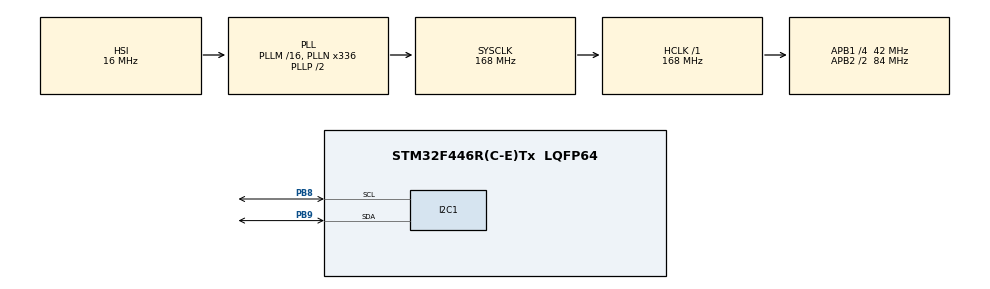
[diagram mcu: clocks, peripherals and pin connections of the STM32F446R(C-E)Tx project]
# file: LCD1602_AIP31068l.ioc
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I2C1.I2C_Mode=I2C_Fast
Mcu.Family=STM32F4
Mcu.Name=STM32F446R(C-E)Tx
Mcu.Package=LQFP64
NVIC.PriorityGroup=NVIC_PRIORITYGROUP_4
PA13.Mode=Serial_Wire
PA13.Signal=SYS_JTMS-SWDIO
PA14.Mode=Serial_Wire
PA14.Signal=SYS_JTCK-SWCLK
PB8.Mode=I2C
PB8.Signal=I2C1_SCL
PB9.Mode=I2C
PB9.Signal=I2C1_SDA
ProjectManager.HeapSize=0x200
ProjectManager.StackSize=0x400
ProjectManager.TargetToolchain=MDK-ARM V5.32
RCC.AHBFreq_Value=168000000
RCC.APB1CLKDivider=RCC_HCLK_DIV4
RCC.APB1Freq_Value=42000000
RCC.APB1TimFreq_Value=84000000
RCC.APB2CLKDivider=RCC_HCLK_DIV2
RCC.APB2Freq_Value=84000000
RCC.APB2TimFreq_Value=168000000
RCC.CortexFreq_Value=168000000
RCC.HCLKFreq_Value=168000000
RCC.PLLN=336
RCC.SYSCLKFreq_VALUE=168000000
RCC.SYSCLKSource=RCC_SYSCLKSOURCE_PLLCLK
RCC.USBFreq_Value=168000000
RCC.VCOOutputFreq_Value=336000000
board=custom

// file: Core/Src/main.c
/* USER CODE BEGIN Header */
/**
  ******************************************************************************
  * @file           : main.c
  * @brief          : Main program body
  ******************************************************************************
  * @attention
  *
  * Copyright (c) 2026 STMicroelectronics.
  * All rights reserved.
  *
  * This software is licensed under terms that can be found in the LICENSE file
  * in the root directory of this software component.
  * If no LICENSE file comes with this software, it is provided AS-IS.
  *
  ******************************************************************************
  */
/* USER CODE END Header */
#include "main.h"
#include "i2c.h"
#include "gpio.h"

/* USER CODE BEGIN Includes */
#include "dwt_delay.h"
#include "lcd1602_i2c_aip31068l.h"
/* USER CODE END Includes */

void SystemClock_Config(void);

int main(void)
{

  /* MCU Configuration--------------------------------------------------------*/

  /* Reset of all peripherals, Initializes the Flash interface and the Systick. */
  HAL_Init();

  /* Configure the system clock */
  SystemClock_Config();

  /* Initialize all configured peripherals */
  MX_GPIO_Init();
  MX_I2C1_Init();
  /* USER CODE BEGIN 2 */

	/**
   * IMPORTANT:
   * Initialize DWT after clocks so SystemCoreClock is correct.
   * DWT requires TRCENA to access counters. [2](http://www.dinceraydin.com/lcd/commands.htm)
   */
  (void)DWT_Delay_Init();

/* Initialize LCD (includes ~60ms power-on wait and basic init commands) */
  lcd_init();
  lcd_backlight_init();              // initialize PCA9633 backlight driver (PCA9633 must be mounted on the module)
  lcd_backlight_set_brightness(255); // 0..255 (try 255 for max)

  lcd_clear();
  lcd_set_cursor(0, 0);
	lcd_puts("STM32F446RE");
  lcd_set_cursor(0, 1);
  lcd_puts("DFR0555 + DWT");

 /* Small demo: shift display right then left */
  DWT_DelayUs(1000000);   /* 1000 ms */
  lcd_scroll(true, 3);
  DWT_DelayUs(1000000);
  lcd_scroll(false, 3);

  /* Custom character demo */
  const uint8_t smile[8] = {
      0b00000,
      0b01010,
      0b01010,
      0b00000,
      0b10001,
      0b01110,
      0b00000,
      0b00000
  };
  lcd_create_char(0, smile);
  lcd_set_cursor(15, 1);
  lcd_put_custom(0);

  /* USER CODE END 2 */

  /* Infinite loop */
  while (1)
  {

  }
}

void SystemClock_Config(void)
{
  RCC_OscInitTypeDef RCC_OscInitStruct = {0};
  RCC_ClkInitTypeDef RCC_ClkInitStruct = {0};

  /** Configure the main internal regulator output voltage
  */
  __HAL_RCC_PWR_CLK_ENABLE();
  __HAL_PWR_VOLTAGESCALING_CONFIG(PWR_REGULATOR_VOLTAGE_SCALE1);

  /** Initializes the RCC Oscillators according to the specified parameters
  * in the RCC_OscInitTypeDef structure.
  */
  RCC_OscInitStruct.OscillatorType = RCC_OSCILLATORTYPE_HSI;
  RCC_OscInitStruct.HSIState = RCC_HSI_ON;
  RCC_OscInitStruct.HSICalibrationValue = RCC_HSICALIBRATION_DEFAULT;
  RCC_OscInitStruct.PLL.PLLState = RCC_PLL_ON;
  RCC_OscInitStruct.PLL.PLLSource = RCC_PLLSOURCE_HSI;
  RCC_OscInitStruct.PLL.PLLM = 16;
  RCC_OscInitStruct.PLL.PLLN = 336;
  RCC_OscInitStruct.PLL.PLLP = RCC_PLLP_DIV2;
  RCC_OscInitStruct.PLL.PLLQ = 2;
  RCC_OscInitStruct.PLL.PLLR = 2;
  if (HAL_RCC_OscConfig(&RCC_OscInitStruct) != HAL_OK)
  {
    Error_Handler();
  }

  /** Initializes the CPU, AHB and APB buses clocks
  */
  RCC_ClkInitStruct.ClockType = RCC_CLOCKTYPE_HCLK|RCC_CLOCKTYPE_SYSCLK
                              |RCC_CLOCKTYPE_PCLK1|RCC_CLOCKTYPE_PCLK2;
  RCC_ClkInitStruct.SYSCLKSource = RCC_SYSCLKSOURCE_PLLCLK;
  RCC_ClkInitStruct.AHBCLKDivider = RCC_SYSCLK_DIV1;
  RCC_ClkInitStruct.APB1CLKDivider = RCC_HCLK_DIV4;
  RCC_ClkInitStruct.APB2CLKDivider = RCC_HCLK_DIV2;

  if (HAL_RCC_ClockConfig(&RCC_ClkInitStruct, FLASH_LATENCY_5) != HAL_OK)
  {
    Error_Handler();
  }
}

void Error_Handler(void)
{
  __disable_irq();
  while (1)
  {
  }
}
